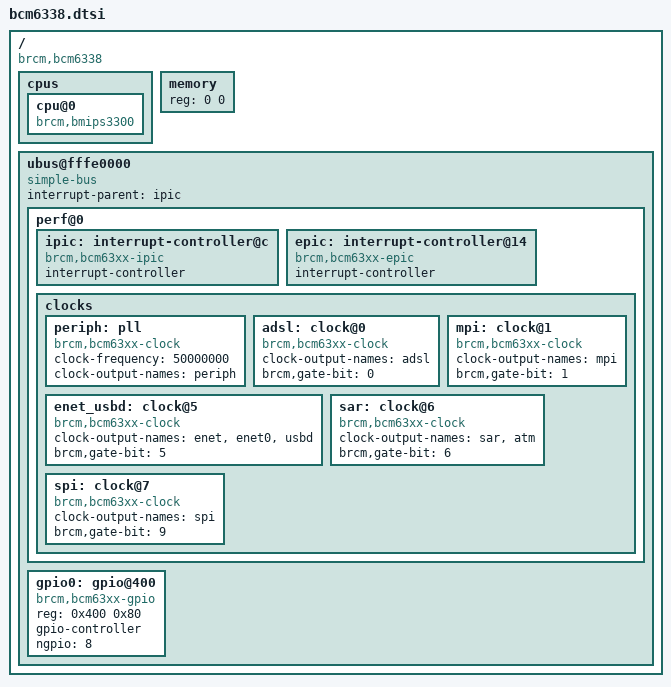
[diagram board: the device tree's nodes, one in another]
/*
 * Device Tree Include file for Broadcom BCM6338 SoC
 *
 * Copyright (C) 2012 Jonas Gorski <jonas.gorski@gmail.com>
 *
 * This file is licensed under the terms of the GNU General Public License
 * version 2.  This program is licensed "as is" without any warranty of any
 * kind, whether express or implied.
 */

/ {
	#address-cells = <1>;
	#size-cells = <1>;
	compatible = "brcm,bcm6338";

	cpus {
		cpu@0 {
			compatible = "brcm,bmips3300", "mips,mips4Kc";
		};
	};

	memory { device_type = "memory"; reg = <0 0>; };

	ubus@fffe0000 {
		#address-cells = <1>;
		#size-cells = <1>;
		ranges = <0 0xfffe0000 0x20000>;
		compatible = "simple-bus";

		interrupt-parent = <&ipic>;

		perf@0 {
			ipic: interrupt-controller@c {
				compatible = "brcm,bcm63xx-ipic";
				interrupt-controller;
				#interrupt-cells = <1>;
			};

			epic: interrupt-controller@14 {
				compatible = "brcm,bcm63xx-epic";
				interrupt-controller;
				#interrupt-cells = <2>;
			};

			clocks {
				#address-cells = <1>;
				#size-cells = <0>;

				periph: pll {
					compatible = "brcm,bcm63xx-clock";
					#clock-cells = <0>;
					clock-frequency = <50000000>;
					clock-output-names = "periph";
				};

				adsl: clock@0 {
					compatible = "brcm,bcm63xx-clock";
					#clock-cells = <0>;
					clock-output-names = "adsl";
					brcm,gate-bit = <0>;
				};

				mpi: clock@1 {
					compatible = "brcm,bcm63xx-clock";
					#clock-cells = <0>;
					clock-output-names = "mpi";
					brcm,gate-bit = <1>;
				};

				enet_usbd: clock@5 {
					#clock-cells = <0>;
					compatible = "brcm,bcm63xx-clock";
					clock-output-names = "enet", "enet0", "usbd";
					brcm,gate-bit = <5>;
				};

				sar: clock@6 {
					compatible = "brcm,bcm63xx-clock";
					#clock-cells = <0>;
					clock-output-names = "sar", "atm";
					brcm,gate-bit = <6>;
				};

				spi: clock@7 {
					compatible = "brcm,bcm63xx-clock";
					#clock-cells = <0>;
					clock-output-names = "spi";
					brcm,gate-bit = <9>;
				};
			};
		};

		gpio0: gpio@400 {
			compatible = "brcm,bcm63xx-gpio";
			reg = <0x400 0x80>;
			gpio-controller;
			#gpio-cells = <2>;
			ngpio = <8>;
		};
	};
};
